# ESP32-S31 register map
Vendor: ESPRESSIF SYSTEMS (SHANGHAI) CO., LTD.; Series: ESP32 S-Series; File version: 1
CPU: RV32IMAFC r0p0, little endian, no MPU, FPU, 0 interrupt priority bits
Address unit: 32 bits
Registers are 32-bit, read-write, reset 0x0 unless marked. A register's access mark holds for its fields unless they carry their own. Offsets are from the block's base; [hi:lo] are bit positions; lines under a group give offsets from that group; {n}, {i} and the like mark numbered series.

## AHB_DMA — AHB_DMA Peripheral
Base 0x20343000
{0x0+0x10*i} IN_INT_CH{i} (i=0..4) group — Cluster IN_INT_CH{i}, containing IN_INT_RAW_CH?, IN_INT_ST_CH?, IN_INT_ENA_CH?, IN_INT_CLR_CH?
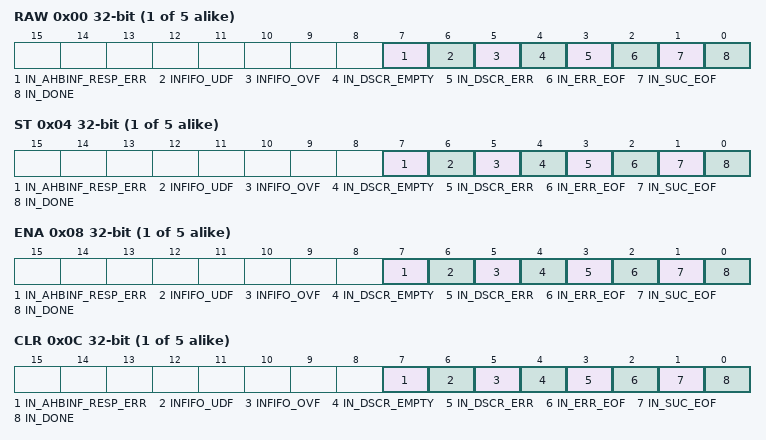
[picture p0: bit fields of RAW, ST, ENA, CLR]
  0x00 RAW — Raw interrupt status of RX channel 0
    [7] IN_AHBINF_RESP_ERR — The raw interrupt status of AHB_DMA_IN_RESP_ERR_CH%s_INT.
    [6] INFIFO_UDF — The raw interrupt status of AHB_DMA_INFIFO_UDF_CH%s_INT.
    [5] INFIFO_OVF — The raw interrupt status of AHB_DMA_INFIFO_OVF_CH%s_INT.
    [4] IN_DSCR_EMPTY — The raw interrupt status of AHB_DMA_IN_DSCR_EMPTY_CH%s_INT.
    [3] IN_DSCR_ERR — The raw interrupt status of AHB_DMA_IN_DSCR_ERR_CH%s_INT.
    [2] IN_ERR_EOF — The raw interrupt status of AHB_DMA_IN_ERR_EOF_CH%s_INT.
    [1] IN_SUC_EOF — The raw interrupt status of AHB_DMA_IN_SUC_EOF_CH%s_INT.
    [0] IN_DONE — The raw interrupt status of AHB_DMA_IN_DONE_CH%s_INT.
  0x04 ST ro — Masked interrupt status of RX channel 0
    [7] IN_AHBINF_RESP_ERR — The masked interrupt status of AHB_DMA_IN_RESP_ERR_CH%s_INT.
    [6] INFIFO_UDF — The masked interrupt status of AHB_DMA_INFIFO_UDF_CH%s_INT.
    [5] INFIFO_OVF — The masked interrupt status of AHB_DMA_INFIFO_OVF_CH%s_INT.
    [4] IN_DSCR_EMPTY — The masked interrupt status of AHB_DMA_IN_DSCR_EMPTY_CH%s_INT.
    [3] IN_DSCR_ERR — The masked interrupt status of AHB_DMA_IN_DSCR_ERR_CH%s_INT.
    [2] IN_ERR_EOF — The masked interrupt status of AHB_DMA_IN_ERR_EOF_CH%s_INT.
    [1] IN_SUC_EOF — The masked interrupt status of AHB_DMA_IN_SUC_EOF_CH%s_INT.
    [0] IN_DONE — The masked interrupt status of AHB_DMA_IN_DONE_CH%s_INT.
  0x08 ENA — Interrupt enable bits of RX channel 0
    [7] IN_AHBINF_RESP_ERR — Write 1 to enable AHB_DMA_IN_RESP_ERR_CH%s_INT.
    [6] INFIFO_UDF — Write 1 to enable AHB_DMA_INFIFO_UDF_CH%s_INT.
    [5] INFIFO_OVF — Write 1 to enable AHB_DMA_INFIFO_OVF_CH%s_INT.
    [4] IN_DSCR_EMPTY — Write 1 to enable AHB_DMA_IN_DSCR_EMPTY_CH%s_INT.
    [3] IN_DSCR_ERR — Write 1 to enable AHB_DMA_IN_DSCR_ERR_CH%s_INT.
    [2] IN_ERR_EOF — Write 1 to enable AHB_DMA_IN_ERR_EOF_CH%s_INT.
    [1] IN_SUC_EOF — Write 1 to enable AHB_DMA_IN_SUC_EOF_CH%s_INT.
    [0] IN_DONE — Write 1 to enable AHB_DMA_IN_DONE_CH%s_INT.
  0x0C CLR wo — Interrupt clear bits of RX channel 0
    [7] IN_AHBINF_RESP_ERR write-1-clears — Write 1 to clear AHB_DMA_IN_RESP_ERR_CH%s_INT.
    [6] INFIFO_UDF write-1-clears — Write 1 to clear AHB_DMA_INFIFO_UDF_CH%s_INT.
    [5] INFIFO_OVF write-1-clears — Write 1 to clear AHB_DMA_INFIFO_OVF_CH%s_INT.
    [4] IN_DSCR_EMPTY write-1-clears — Write 1 to clear AHB_DMA_IN_DSCR_EMPTY_CH%s_INT.
    [3] IN_DSCR_ERR write-1-clears — Write 1 to clear AHB_DMA_IN_DSCR_ERR_CH%s_INT.
    [2] IN_ERR_EOF write-1-clears — Write 1 to clear AHB_DMA_IN_ERR_EOF_CH%s_INT.
    [1] IN_SUC_EOF write-1-clears — Write 1 to clear AHB_DMA_IN_SUC_EOF_CH%s_INT.
    [0] IN_DONE write-1-clears — Write 1 to clear AHB_DMA_IN_DONE_CH%s_INT.
{0x50+0x10*i} OUT_INT_CH{i} (i=0..4) group — Cluster OUT_INT_CH{i}, containing OUT_INT_RAW_CH?, OUT_INT_ST_CH?, OUT_INT_ENA_CH?, OUT_INT_CLR_CH?
  0x00 RAW — Raw interrupt status of TX channel 0
    [6] OUT_AHBINF_RESP_ERR — The raw interrupt status of AHB_DMA_OUT_RESP_ERR_CH%s_INT.
    [5] OUTFIFO_UDF — The raw interrupt status of AHB_DMA_OUTFIFO_UDF_CH%s_INT.
    [4] OUTFIFO_OVF — The raw interrupt status of AHB_DMA_OUTFIFO_OVF_CH%s_INT.
    [3] OUT_TOTAL_EOF — The raw interrupt status of AHB_DMA_OUT_TOTAL_EOF_CH%s_INT.
    [2] OUT_DSCR_ERR — The raw interrupt status of AHB_DMA_OUT_DSCR_ERR_CH%s_INT.
    [1] OUT_EOF — The raw interrupt status of AHB_DMA_OUT_EOF_CH%s_INT.
    [0] OUT_DONE — The raw interrupt status of AHB_DMA_OUT_DONE_CH%s_INT.
  0x04 ST ro — Masked interrupt status of TX channel 0
    [6] OUT_AHBINF_RESP_ERR — The masked interrupt status of AHB_DMA_OUT_RESP_ERR_CH%s_INT.
    [5] OUTFIFO_UDF — The masked interrupt status of AHB_DMA_OUTFIFO_UDF_CH%s_INT.
    [4] OUTFIFO_OVF — The masked interrupt status of AHB_DMA_OUTFIFO_OVF_CH%s_INT.
    [3] OUT_TOTAL_EOF — The masked interrupt status of AHB_DMA_OUT_TOTAL_EOF_CH%s_INT.
    [2] OUT_DSCR_ERR — The masked interrupt status of AHB_DMA_OUT_DSCR_ERR_CH%s_INT.
    [1] OUT_EOF — The masked interrupt status of AHB_DMA_OUT_EOF_CH%s_INT.
    [0] OUT_DONE — The masked interrupt status of AHB_DMA_OUT_DONE_CH%s_INT.
  0x08 ENA — Interrupt enable bits of TX channel 0
    [6] OUT_AHBINF_RESP_ERR — Write 1 to enable AHB_DMA_OUT_RESP_ERR_CH%s_INT.
    [5] OUTFIFO_UDF — Write 1 to enable AHB_DMA_OUTFIFO_UDF_CH%s_INT.
    [4] OUTFIFO_OVF — Write 1 to enable AHB_DMA_OUTFIFO_OVF_CH%s_INT.
    [3] OUT_TOTAL_EOF — Write 1 to enable AHB_DMA_OUT_TOTAL_EOF_CH%s_INT.
    [2] OUT_DSCR_ERR — Write 1 to enable AHB_DMA_OUT_DSCR_ERR_CH%s_INT.
    [1] OUT_EOF — Write 1 to enable AHB_DMA_OUT_EOF_CH%s_INT.
    [0] OUT_DONE — Write 1 to enable AHB_DMA_OUT_DONE_CH%s_INT.
  0x0C CLR wo — Interrupt clear bits of TX channel 0
    [6] OUT_AHBINF_RESP_ERR write-1-clears — Write 1 to clear AHB_DMA_OUT_RESP_ERR_CH%s_INT.
    [5] OUTFIFO_UDF write-1-clears — Write 1 to clear AHB_DMA_OUTFIFO_UDF_CH%s_INT.
    [4] OUTFIFO_OVF write-1-clears — Write 1 to clear AHB_DMA_OUTFIFO_OVF_CH%s_INT.
    [3] OUT_TOTAL_EOF write-1-clears — Write 1 to clear AHB_DMA_OUT_TOTAL_EOF_CH%s_INT.
    [2] OUT_DSCR_ERR write-1-clears — Write 1 to clear AHB_DMA_OUT_DSCR_ERR_CH%s_INT.
    [1] OUT_EOF write-1-clears — Write 1 to clear AHB_DMA_OUT_EOF_CH%s_INT.
    [0] OUT_DONE write-1-clears — Write 1 to clear AHB_DMA_OUT_DONE_CH%s_INT.
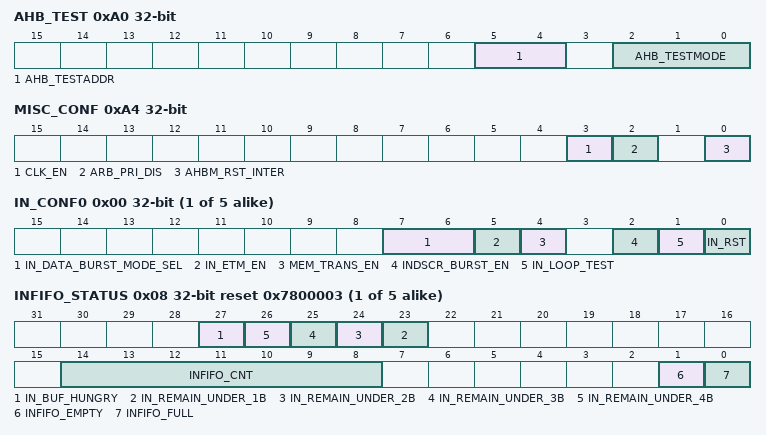
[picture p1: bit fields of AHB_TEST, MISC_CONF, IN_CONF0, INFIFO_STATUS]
0xA0 AHB_TEST — reserved
  [5:4] AHB_TESTADDR — reserved
  [2:0] AHB_TESTMODE — reserved
0xA4 MISC_CONF — Miscellaneous register
  [3] CLK_EN — Configures clock gating.\\0: Support clock only when the application writes registers.\\ 1: Always force the clock on for registers.\\
  [2] ARB_PRI_DIS — Configures whether to disable the fixed-priority channel arbitration.\\0: Enable\\1: Disable\\
  [0] AHBM_RST_INTER — Write 1 and then 0 to reset the internal AHB FSM.
0xA8 DATE reset 0x2407310 — Version control register
  [31:0] DATE — Version control register.
{0x100+0x100*i} CH{i} (i=0..4) group — Cluster CH{i}, containing IN_CONF0_CH?, IN_CONF1_CH?, INFIFO_STATUS_CH?, IN_POP_CH?, IN_LINK_CH?, IN_LINK_ADDR_CH?, IN_STATE_CH?, IN_SUC_EOF_DES_ADDR_CH?, IN_ERR_EOF_DES_ADDR_CH?, IN_DONE_DES_ADDR_CH?, IN_DSCR_CH?, IN_DSCR_BF0_CH?, IN_DSCR_BF1_CH?, IN_PRI_CH?, IN_PERI_SEL_CH?, RX_CH_ARB_WEIGH_CH?, RX_ARB_WEIGH_OPT_DIR_CH?, OUT_CONF0_CH?, OUT_CONF1_CH?, OUTFIFO_STATUS_CH?, OUT_PUSH_CH?, OUT_LINK_CH?, OUT_LINK_ADDR_CH?, OUT_STATE_CH?, OUT_EOF_DES_ADDR_CH?, OUT_EOF_BFR_DES_ADDR_CH?, OUT_DONE_DES_ADDR_CH?, OUT_DSCR_CH?, OUT_DSCR_BF0_CH?, OUT_DSCR_BF1_CH?, OUT_PRI_CH?, OUT_PERI_SEL_CH?, TX_CH_ARB_WEIGH_CH?, TX_ARB_WEIGH_OPT_DIR_CH?
  0x00 IN_CONF0 — Configuration register 0 of RX channel 0
    [7:6] IN_DATA_BURST_MODE_SEL — Configures max burst size for Rx channel%s.\\2'b00: single\\ 2'b01: incr4\\ 2'b10: incr8\\ 2'b11: incr16\\
    [5] IN_ETM_EN — Configures whether to enable ETM control for RX channel%s.\\0: Disable\\1: Enable\\
    [4] MEM_TRANS_EN — Configures whether to enable memory-to-memory data transfer.\\0: Disable\\1: Enable\\
    [2] INDSCR_BURST_EN — Configures whether to enable INCR burst transfer for RX channel %s to read descriptors.\\0: Disable\\1: Enable\\
    [1] IN_LOOP_TEST — Reserved.
    [0] IN_RST — Write 1 and then 0 to reset AHB_DMA channel 0 RX FSM and RX FIFO pointer.
  0x04 IN_CONF1 — Configuration register 1 of RX channel 0
    [12] IN_CHECK_OWNER — Configures whether to enable owner bit check for RX channel %s.\\0: Disable\\1: Enable\\
  0x08 INFIFO_STATUS ro reset 0x7800003 — Receive FIFO status of RX channel 0
    [27] IN_BUF_HUNGRY — reserved
    [n+22] IN_REMAIN_UNDER_{n}B (n=1..4) — reserved
    [14:8] INFIFO_CNT — Represents the number of data bytes in L1 RX FIFO for RX channel %s.
    [1] INFIFO_EMPTY — Represents whether L1 RX FIFO is empty.\\0: Not empty\\1: Empty\\
    [0] INFIFO_FULL — Represents whether L1 RX FIFO is full.\\0: Not Full\\1: Full\\
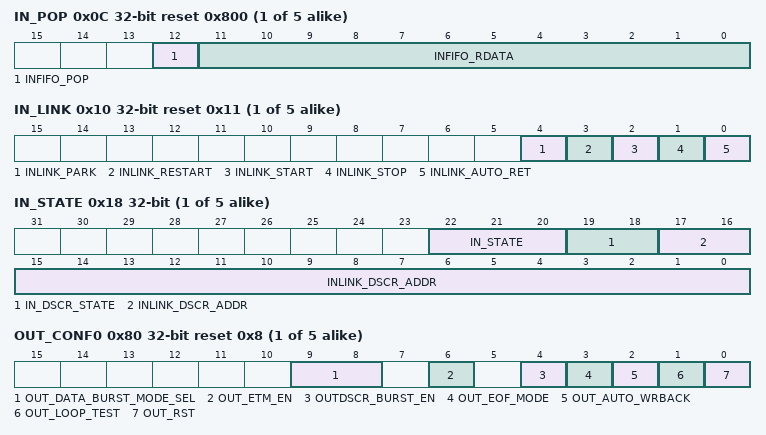
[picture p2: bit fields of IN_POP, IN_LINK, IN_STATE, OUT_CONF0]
  0x0C IN_POP access per field reset 0x800 — Pop control register of RX channel 0
    [12] INFIFO_POP wo — Configures whether to pop data from AHB_DMA FIFO.\\0: Invalid. No effect\\1: Pop\\
    [11:0] INFIFO_RDATA ro — Represents the data popped from AHB_DMA FIFO.
  0x10 IN_LINK access per field reset 0x11 — Linked list descriptor configuration and control register of RX channel 0
    [4] INLINK_PARK ro — Represents the status of the receive descriptor's FSM.\\0: Running\\1: Idle\\
    [3] INLINK_RESTART wo — Configures whether to restart RX channel %s for AHB_DMA transfer.\\0: Invalid. No effect\\1: Restart\\
    [2] INLINK_START wo — Configures whether to enable AHB_DMA's RX channel %s for data transfer.\\0: Disable\\1: Enable\\
    [1] INLINK_STOP wo — Configures whether to stop AHB_DMA's RX channel %s from receiving data.\\0: Invalid. No effect\\1: Stop\\
    [0] INLINK_AUTO_RET rw — Configures whether to return to current receive descriptor's address when there are some errors in current receiving data.\\0: Not return\\1: Return\\
  0x14 IN_LINK_ADDR — Link list descriptor address configuration of RX channel 0
    [31:0] INLINK_ADDR — Configures the 32 bits of the first receive descriptor's address.
  0x18 IN_STATE ro — Receive status of RX channel 0
    [22:20] IN_STATE — reserved
    [19:18] IN_DSCR_STATE — reserved
    [17:0] INLINK_DSCR_ADDR — Represents the address of the lower 18 bits of the next receive descriptor to be processed.
  0x1C IN_SUC_EOF_DES_ADDR ro — Receive descriptor address when EOF occurs on RX channel 0
    [31:0] IN_SUC_EOF_DES_ADDR — Represents the address of the receive descriptor when the EOF bit in this descriptor is 1.
  0x20 IN_ERR_EOF_DES_ADDR ro — Receive descriptor address when errors occur of RX channel 0
    [31:0] IN_ERR_EOF_DES_ADDR — Represents the address of the receive descriptor when there are some errors in the currently received data.
  0x24 IN_DONE_DES_ADDR ro — RX_done inlink descriptor address of RX channel 0
    [31:0] IN_DONE_DES_ADDR — Represents the address of the inlink descriptor when this descriptor is completed .
  0x28 IN_DSCR ro — Current receive descriptor address of RX channel 0
    [31:0] INLINK_DSCR — Represents the address of the next receive descriptor x+1 pointed by the current receive descriptor that has already been fetched.
  0x2C IN_DSCR_BF0 ro — The last receive descriptor address of RX channel 0
    [31:0] INLINK_DSCR_BF0 — Represents the address of the current receive descriptor x that has already been fetched.
  0x30 IN_DSCR_BF1 ro — The second-to-last receive descriptor address of RX channel 0
    [31:0] INLINK_DSCR_BF1 — Represents the address of the previous receive descriptor x-1 that has already been fetched.
  0x34 IN_PRI — Priority register of RX channel 0
    [3:0] RX_PRI — Configures the priority of RX channel %s.The larger of the value, the higher of the priority.
  0x38 IN_PERI_SEL reset 0x3F — Peripheral selection register of RX channel 0
    [5:0] PERI_IN_SEL — Configures the peripheral connected to RX channel %s.\\ 0: UHCI0\\ 1: I2S0-0\\ 2: I2S0-1\\ 3: I2S0-2\\ 4: I2S0-3\\ 5: I2S1-0\\ 6: I2S1-1\\ 7: I2S1-2\\ 8: I2S1-3\\ 9: ADC_DAC\\ 10: RMT\\ 11: Sample_rate_convert-0\\ 12: Sample_rate_convert-1 \\ 13: Cordic\\ 14: PVT0 \\ 15: DUMMY \\
  0x3C RX_CH_ARB_WEIGH — RX channel 0 arbitration weight configuration register
    [3:0] RX_CH_ARB_WEIGH — Configures the weight(i.e the number of tokens) of RX channel%s
  0x40 RX_ARB_WEIGH_OPT_DIR — RX channel 0 weight arbitration optimization enable register
    [0] RX_ARB_WEIGH_OPT_DIR — reserved
  0x80 OUT_CONF0 reset 0x8 — Configuration register 0 of TX channel 0
    [9:8] OUT_DATA_BURST_MODE_SEL — Configures max burst size for TX channel%s.\\2'b00: single\\ 2'b01: incr4\\ 2'b10: incr8\\ 2'b11: incr16\\
    [6] OUT_ETM_EN — Configures whether to enable ETM control for TX channel %s.\\0: Disable\\1: Enable\\
    [4] OUTDSCR_BURST_EN — Configures whether to enable INCR burst transfer for TX channel %s reading descriptors.\\0: Disable\\1: Enable\\
    [3] OUT_EOF_MODE — Configures when to generate EOF flag.\\0: EOF flag for TX channel %s is generated when data to be transmitted has been pushed into FIFO in AHB_DMA.\\ 1: EOF flag for TX channel %s is generated when data to be transmitted has been popped from FIFO in AHB_DMA.\\
    [2] OUT_AUTO_WRBACK — Configures whether to enable automatic outlink write-back when all the data in TX FIFO has been transmitted.\\0: Disable\\1: Enable\\
    [1] OUT_LOOP_TEST — Reserved.
    [0] OUT_RST — Configures the reset state of AHB_DMA channel %s TX FSM and TX FIFO pointer.\\0: Release reset\\1: Reset\\
  0x84 OUT_CONF1 — Configuration register 1 of TX channel 0
    [12] OUT_CHECK_OWNER — Configures whether to enable owner bit check for TX channel %s.\\0: Disable\\1: Enable\\
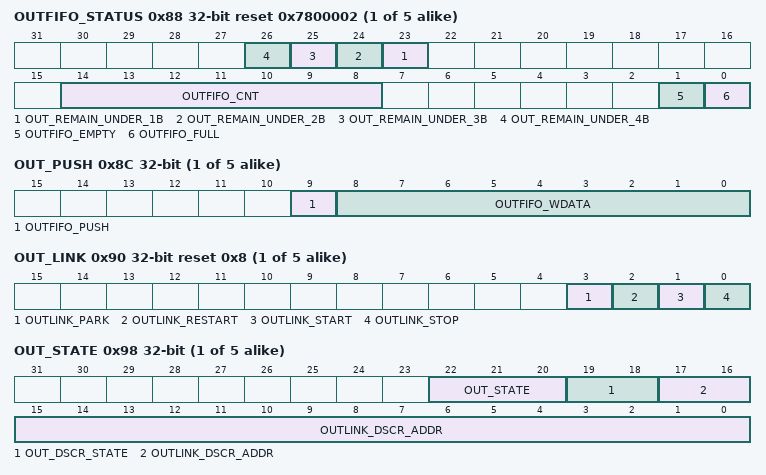
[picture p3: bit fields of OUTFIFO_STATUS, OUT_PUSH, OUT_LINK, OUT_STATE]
  0x88 OUTFIFO_STATUS ro reset 0x7800002 — Transmit FIFO status of TX channel 0
    [n+22] OUT_REMAIN_UNDER_{n}B (n=1..4) — Reserved.
    [14:8] OUTFIFO_CNT — Represents the number of data bytes in L1 TX FIFO for TX channel %s.
    [1] OUTFIFO_EMPTY — Represents whether L1 TX FIFO is empty.\\0: Not empty\\1: Empty\\
    [0] OUTFIFO_FULL — Represents whether L1 TX FIFO is full.\\0: Not Full\\1: Full\\
  0x8C OUT_PUSH access per field — Push control register of TX channel 0
    [9] OUTFIFO_PUSH wo — Configures whether to push data into AHB_DMA FIFO.\\0: Invalid. No effect\\1: Push\\
    [8:0] OUTFIFO_WDATA rw — Configures the data that need to be pushed into AHB_DMA FIFO.
  0x90 OUT_LINK access per field reset 0x8 — Linked list descriptor configuration and control register of TX channel 0
    [3] OUTLINK_PARK ro — Represents the status of the transmit descriptor's FSM.\\0: Running\\1: Idle\\
    [2] OUTLINK_RESTART wo — Configures whether to restart TX channel %s for AHB_DMA transfer.\\0: Invalid. No effect\\1: Restart\\
    [1] OUTLINK_START wo — Configures whether to enable AHB_DMA's TX channel %s for data transfer.\\0: Disable\\1: Enable\\
    [0] OUTLINK_STOP wo — Configures whether to stop AHB_DMA's TX channel %s from transmitting data.\\0: Invalid. No effect\\1: Stop\\
  0x94 OUT_LINK_ADDR — Link list descriptor address configuration of TX channel 0
    [31:0] OUTLINK_ADDR — Configures the 32 bits of the first receive descriptor's address.
  0x98 OUT_STATE ro — Transmit status of TX channel 0
    [22:20] OUT_STATE — reserved
    [19:18] OUT_DSCR_STATE — reserved
    [17:0] OUTLINK_DSCR_ADDR — Represents the lower 18 bits of the address of the next transmit descriptor to be processed.
  0x9C OUT_EOF_DES_ADDR ro — Transmit descriptor address when EOF occurs on TX channel 0
    [31:0] OUT_EOF_DES_ADDR — Represents the address of the transmit descriptor when the EOF bit in this descriptor is 1.
  0xA0 OUT_EOF_BFR_DES_ADDR ro — The last transmit descriptor address when EOF occurs on TX channel 0
    [31:0] OUT_EOF_BFR_DES_ADDR — Represents the address of the transmit descriptor before the last transmit descriptor.
  0xA4 OUT_DONE_DES_ADDR ro — TX done outlink descriptor address of TX channel 0
    [31:0] OUT_DONE_DES_ADDR — Represents the address of the outlink descriptor when this descriptor is completed.
  0xA8 OUT_DSCR ro — Current transmit descriptor address of TX channel 0
    [31:0] OUTLINK_DSCR — Represents the address of the next transmit descriptor y+1 pointed by the current transmit descriptor that has already been fetched.
  0xAC OUT_DSCR_BF0 ro — The last transmit descriptor address of TX channel 0
    [31:0] OUTLINK_DSCR_BF0 — Represents the address of the current transmit descriptor y that has already been fetched.
  0xB0 OUT_DSCR_BF1 ro — The second-to-last transmit descriptor address of TX channel 0
    [31:0] OUTLINK_DSCR_BF1 — Represents the address of the previous transmit descriptor y-1 that has already been fetched.
  0xB4 OUT_PRI — Priority register of TX channel 0
    [3:0] TX_PRI — Configures the priority of TX channel %s.The larger of the value, the higher of the priority.
  0xB8 OUT_PERI_SEL reset 0x3F — Peripheral selection register of TX channel 0
    [5:0] PERI_OUT_SEL — Configures the peripheral connected to TX channel %s.\\ 0: UHCI0\\ 1: I2S0-0\\ 2: I2S0-1\\ 3: I2S0-2\\ 4: I2S0-3\\ 5: I2S1-0\\ 6: I2S1-1\\ 7: I2S1-2\\ 8: I2S1-3\\ 9: ADC_DAC\\ 10: RMT\\ 11: Sample_rate_convert-0\\ 12: Sample_rate_convert-1 \\ 13: Cordic\\ 14: PVT0 \\ 15: DUMMY\\
  0xBC TX_CH_ARB_WEIGH — TX channel 0 arbitration weight configuration register
    [3:0] TX_CH_ARB_WEIGH — Configures the weight(i.e the number of tokens) of TX channel%s
  0xC0 TX_ARB_WEIGH_OPT_DIR — TX channel 0 weight arbitration optimization enable register
    [0] TX_ARB_WEIGH_OPT_DIR — reserved
0x600 INTR_MEM_START_ADDR — Accessible address space start address configuration register
  [31:0] ACCESS_INTR_MEM_START_ADDR — Configures the start address of accessible address space.
0x604 INTR_MEM_END_ADDR reset 0xFFFFFFFF — Accessible address space end address configuration register
  [31:0] ACCESS_INTR_MEM_END_ADDR — Configures the end address of accessible address space.
0x608 ARB_TIMEOUT — TX arbitration timeout configuration register
  [15:0] ARB_TIMEOUT — Configures the time slot. Measurement unit: AHB bus clock cycle.
0x610 WEIGHT_EN — TX weight arbitration enable register
  [0] WEIGHT_EN — Configures whether to enable weight arbitration.\\0: Disable\\1: Enable\\
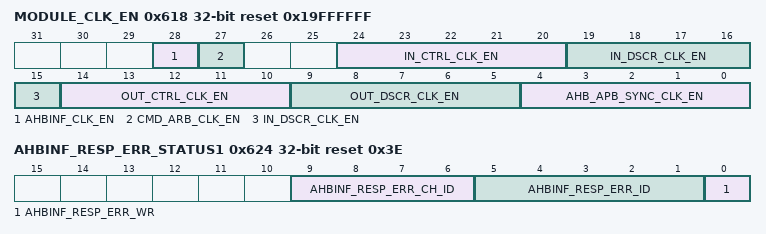
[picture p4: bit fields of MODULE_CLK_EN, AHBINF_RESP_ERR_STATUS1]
0x618 MODULE_CLK_EN reset 0x19FFFFFF — Module clock force on register
  [28] AHBINF_CLK_EN — Configures whether to force on ahbinf module clock. \\0 : Not force on ahbinf clock \\1 : Force on ahbinf clock\\
  [27] CMD_ARB_CLK_EN — Configures whether to force on cmd_arb module clock. \\0 : Not force on cmd_arb clock \\1 : Force on cmd_arb clock\\
  [24:20] IN_CTRL_CLK_EN — Configures whether to force on in_ctrl 4~0 module clock. For bit n:\\0 : Not force on in_ctrl n clock \\1 : Force on in_ctrl n clock\\
  [19:15] IN_DSCR_CLK_EN — Configures whether to force on in_dscr 4~0 module clock. For bit n:\\0 : Not force on in_dscr n clock \\1 : Force on in_dscr n clock\\
  [14:10] OUT_CTRL_CLK_EN — Configures whether to force on out_ctrl 4~0 module clock. For bit n:\\0 : Not force on out_ctrl n clock \\1 : Force on out_ctrl n clock\\
  [9:5] OUT_DSCR_CLK_EN — Configures whether to force on out_dscr 4~0 module clock. For bit n:\\0 : Not force on out_dscr n clock \\1 : Force on out_dscr n clock\\
  [4:0] AHB_APB_SYNC_CLK_EN — Configures whether to force on ahb_apb_sync 4~0 module clock. For bit n:\\0 : Not force on ahb_apb_sync n clock \\1 : Force on ahb_apb_sync n clock\\
0x620 AHBINF_RESP_ERR_STATUS0 ro — AHB response error status 0 register
  [31:0] AHBINF_RESP_ERR_ADDR — Represents the address of the AHB response error.
0x624 AHBINF_RESP_ERR_STATUS1 ro reset 0x3E — AHB response error status 1 register
  [9:6] AHBINF_RESP_ERR_CH_ID — Represents the AHB response error request channel id.bit[3]=1:TX channel.\\bit[3]=0:RX channel.\\
  [5:1] AHBINF_RESP_ERR_ID — Represents the AHB response error request id.
  [0] AHBINF_RESP_ERR_WR — Represents the AHB response error is write request.
